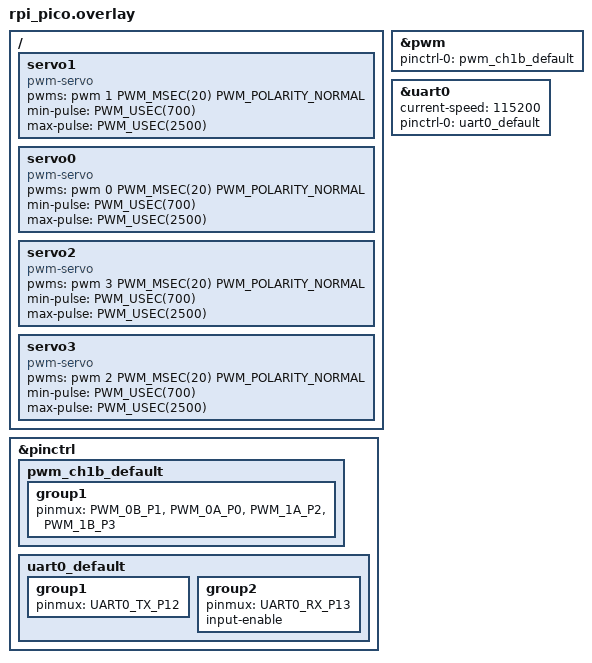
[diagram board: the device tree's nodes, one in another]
#include </home/tatiana/zephyrproject/zephyr/include/zephyr/dt-bindings/pinctrl/rpi-pico-rp2040-pinctrl.h>


/ {
	servo1: servo1 {
		compatible = "pwm-servo";
		pwms = <&pwm 1 PWM_MSEC(20) PWM_POLARITY_NORMAL>;
		min-pulse = <PWM_USEC(700)>;
		max-pulse = <PWM_USEC(2500)>;
	};
	servo0: servo0 {
		compatible = "pwm-servo";
		pwms = <&pwm 0 PWM_MSEC(20) PWM_POLARITY_NORMAL>;
		min-pulse = <PWM_USEC(700)>;
		max-pulse = <PWM_USEC(2500)>;
	};
	servo2: servo2 {
		compatible = "pwm-servo";
		pwms = <&pwm 3 PWM_MSEC(20) PWM_POLARITY_NORMAL>;
		min-pulse = <PWM_USEC(700)>;
		max-pulse = <PWM_USEC(2500)>;
	};
	servo3: servo3 {
		compatible = "pwm-servo";
		pwms = <&pwm 2 PWM_MSEC(20) PWM_POLARITY_NORMAL>;
		min-pulse = <PWM_USEC(700)>;
		max-pulse = <PWM_USEC(2500)>;
	};
	
	
	
	
};



&pinctrl {
	pwm_ch1b_default: pwm_ch1b_default {
		group1 {
			pinmux = 
			<PWM_0B_P1>,
			<PWM_0A_P0>,
			<PWM_1A_P2>,
			<PWM_1B_P3>;
			
		};
	};
};

&pwm {
	status = "okay";
	pinctrl-0 = <&pwm_ch1b_default>;
	pinctrl-names = "default";
	#address-cells = <1>;
	#size-cells = <0>;
	
};



&uart0 {
	current-speed = <115200>;
	status = "okay";
	pinctrl-0 = <&uart0_default>;
	pinctrl-names = "default";
};

&pinctrl {
	uart0_default: uart0_default {
		group1 {
			pinmux = <UART0_TX_P12>;
		};
		group2 {
			pinmux = <UART0_RX_P13>;
			input-enable;
		};
	};
};



